# N32F030 register map
File version: 1.0
Registers are 32-bit, read-write, reset 0x0 unless marked. A register's access mark holds for its fields unless they carry their own. Offsets are from the block's base; [hi:lo] are bit positions; {n}, {i} and the like mark numbered series; 'fields as' and 'values as' point back to an identical list.

## EPWM — EPWM Register Map
Base 0x40040000
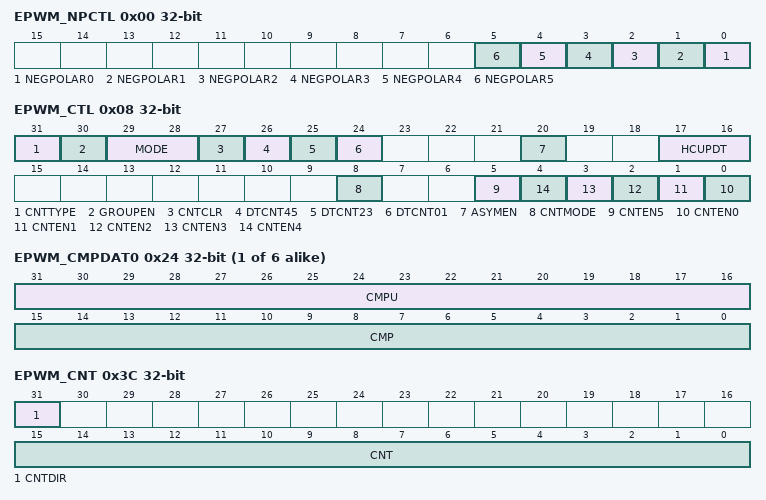
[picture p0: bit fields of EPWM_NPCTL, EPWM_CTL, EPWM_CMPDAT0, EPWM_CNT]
0x00 EPWM_NPCTL — EPWM Negative Polarity Control Register
  [all] fields
    0=PWM output is active high; 1=PWM output is active low
  [n] NEGPOLAR{n} (n=0..5) — PWM{n} Negative Polarity Control. The register bit controls polarity/active state of real PWM output.
0x04 EPWM_CLKDIV — EPWM Clock Select Register
  [3:0] CLKDIV — EPWM Clock Divider (9 Step Divider). Select clock input for PWM timer
    0=1 (HCLK / 2^0); 1=1/2 (HCLK / 2^1); 2=1/4 (HCLK / 2^2); 3=1/8 (HCLK / 2^3); 4=1/16 (HCLK / 2^4); 5=1/32 (HCLK / 2^5); 6=1/64 (HCLK / 2^6); 7=1/128 (HCLK / 2^7); 8=1/256 (HCLK / 2^8)
0x08 EPWM_CTL — EPWM Control Register
  [31] CNTTYPE — PWM Aligned Type Selection
    0=Edge-aligned type; 1=Center-aligned type
  [30] GROUPEN — Group Bit
    0=The signals timing of PWM0, PWM2 and PWM4 are independent; 1=Unify the signals timing of PWM0, PWM2 and PWM4 in the same phase which is controlled by PWM0
  [29:28] MODE — PWM Operating Mode Selection. Note: If th complementary mode is selected, the deadtime insertion is active automatically.
    0=Independent mode; 1=Complementary mode
  [27] CNTCLR — Clear PWM Counter Control Bit. Note: It is automatically cleared by hardware.
    0=Do not clear PWM counter; 1=16-bit PWM counter cleared to 0x000
  [26] DTCNT45 — Dead-zone 4 Generator Enable/Disable (PWM4 and PWM5 Pair for PWM Group). Note: When the dead-zone generator is enabled, the pair of PWM4 and PWM5 becomes a complementary pair for PWM group.
    0=Dead-zone 4 Generator Disabled; 1=Dead-zone 4 Generator Enabled
  [25] DTCNT23 — Dead-zone 2 Generator Enable/Disable (PWM2 and PWM3 Pair for PWM Group). Note: When the dead-zone generator is enabled, the pair of PWM2 and PWM3 becomes a complementary pair for PWM group.
    0=Dead-zone 2 Generator Disabled; 1=Dead-zone 2 Generator Enabled
  [24] DTCNT01 — Dead-zone 0 Generator Enable/Disable (PWM0 and PWM1 Pair for PWM Group). Note: When the dead-zone generator is enabled, the pair of PWM0 and PWM1 becomes a complementary pair for PWM group.
    0=Dead-zone 0 Generator Disabled; 1=Dead-zone 0 Generator Enabled
  [20] ASYMEN — Asymmetric Mode in Center-aligned Type
    0=Symmetric mode in center-aligned type; 1=Asymmetric mode in center-aligned type
  [17:16] HCUPDT — Half Cycle Update Enable for Center-aligned Type
    0=Update PERIOD CMP at pwm_counter = PERIOD (Period); 1=Update PERIOD CMP at pwm_counter = 0; 2=Update PERIOD CMP at half cycle (counter = 0 PERIOD, both update); 3=Update PERIOD CMP at pwm_counter = PERIOD (Period)
  [8] CNTMODE — PWM-timer Auto-reload/One-shot Mode
    0=One-shot mode; 1=Auto-reload mode
  [5] CNTEN5 — PWM-generator 5 Enable/Disable Start Run
    0=Corresponding PWM-timer running Stopped; 1=Corresponding PWM-timer start run Enabled
  [n] CNTEN{n} (n=0..4) — PWM- Generator {n} Enable/Disable Start Run
    values as CNTEN5
0x0C EPWM_PERIOD — EPWM Period Counter Register
  [15:0] PERIOD — PWM Counter/Timer Loaded Value. PERIODn determines the PWM Period. Edge-aligned mode: where xy, could be 01, 23, 45 depending on the selected PWM channel. Note: Any write to PERIODn will take effect in next PWM cycle.
{0x24+4i} EPWM_CMPDAT{i} (i=0..5) — EPWM Comparator Register {i}
  [31:16] CMPU — PWM Comparator Register for UP Counter in Center-aligned Asymmetric Mode. CMPU PERIOD: @ up counter PWM output is keep to Max. duty.
  [15:0] CMP — PWM Comparator Register. CMP determines the PWM Duty. Edge-aligned mode: where xy, could be 01, 23, 45 depending on the selected PWM channel. Note: Any write to CMPn will take effect in next PWM cycle.
0x3C EPWM_CNT ro — EPWM Data Register
  [31] CNTDIR — PWM Counter (Up/Down) Direction
    0=PWM counter is down counting; 1=PWM counter is up counting
  [15:0] CNT — PWM Data Register. User can monitor CNT to know the current value in 16-bit down counter.
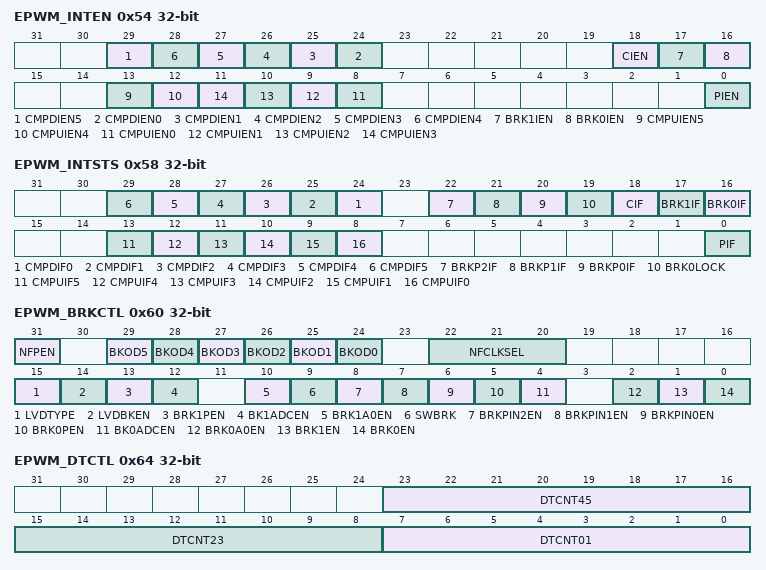
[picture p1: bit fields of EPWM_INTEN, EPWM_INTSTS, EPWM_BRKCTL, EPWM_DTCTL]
0x54 EPWM_INTEN — EPWM Interrupt Enable Register
  [29] CMPDIEN5 — PWM Channel 5 DOWN Interrupt Enable Control. DOWN for Edge-aligned and Center-aligned
    0=Interruptcompare Disabled; 1=Interruptwhen EPWM_CH5 PWM DOWN counter reaches EPWM_CMPDAT5 Enabled
  [n+24] CMPDIEN{n} (n=0..4) — PWM Channel {n} DOWN Interrupt Enable Control. DOWN for Edge-aligned and Center-aligned
    0=Interruptcompare Disabled; 1=interruptwhen EPWM_CH{n} PWM DOWN counter reaches EPWM_CMPDAT{n} Enabled
  [18] CIEN — PWM Central Interrupt Enable Control for Center-aligned only
    0=Interruptwhen EPWM Central Enabled; 1=Interruptwhen EPWM Central Enabled
  [17] BRK1IEN — Fault Brake1 Interrupt Enable Control
    0=BRK1IF trigger PWM interrupt Disabed; 1=BRK1IF trigger PWM interrupt Enabled
  [16] BRK0IEN — Fault Brake0 Interrupt Enable Control
    0=BRK0IF trigger PWM interrupt Disabled; 1=BRK0IF trigger PWM interrupt Enabled
  [13] CMPUIEN5 — PWM Channel 5 UP Interrupt Enable Control. UP for Center-aligned only
    0=PWM Channel 5 UP Interrupt Disabled; 1=Interruptwhen EPWM_CH5 PWM UP counter reaches EPWM_CMPDAT5 Enabled
  [12] CMPUIEN4 — PWM Channel 4 UP Interrupt Enable Control. UP for Center-aligned only
    0=EPWM_CH4 PWM UP counter reaches EPWM_CMPDAT4 interrupt Disabled; 1=EPWM_CH4 PWM UP counter reaches EPWM_CMPDAT4 interrupt Enabled
  [n+8] CMPUIEN{n} (n=0..3) — PWM Channel {n} UP Interrupt Enable Control. UP for Center-aligned only
    0=EPWM_CH{n} PWM UP counter reaches EPWM_CMPDAT{n} interruptDisabled; 1=EPWM_CH{n} PWM UP counter reaches EPWM_CMPDAT{n} interruptEnabled
  [0] PIEN — PWM Channel 0 Period Interrupt Enable Control for Edge-aligned and Center-aligned
    0=EPWM Period interruptDisabled; 1=EPWM Period interruptEnabled
0x58 EPWM_INTSTS — EPWM Interrupt Status Register
  [n+24] CMPDIF{n} (n=0..5) — PWM Channel {n} DOWN Interrupt Flag. Flag is set by hardware when a channel {n} PWM DOWN counter reaches EPWM_CMPDAT{n}. Software can write 1 to clear this bit.
  [22] BRKP2IF — BRK Pin2 Status Flag. Flag is set by pin PWM_BRK_P2 with low pulse event. Software can write 1 to clear this bit.
  [21] BRKP1IF — BRK Pin1 Status Flag. Flag is set by pin PWM_BRK_P1 with low pulse event. Software can write 1 to clear this bit.
  [20] BRKP0IF — BRK Pin0 Status Flag. Flag is set by pin PWM_BRK_P0 with low pulse event. Software can write 1 to clear this bit.
  [19] BRK0LOCK — PWM Brake0 Locked. Note: Software can write 1 to clear this bit.
    0=PWM Brake does not recognize a falling signal at BKP0; 1=When PWM Brake detects a falling signal at pin BKP0, this flag will be set to high, when this bit set high, it helps breaking PWM output even interrupt flag BRK0IF was cleared by CPU before jumping out from sub-routine
  [18] CIF — PWM Channel 0 Central Interrupt Flag. Flag is set by hardware when PWM down counter reaches zero point. Software can write 1 to clear this bit.
  [17] BRK1IF — PWM Brake1 Flag. Note: Software can write 1 to clear this bit.
    0=PWM Brake does not recognize a falling signal at BKP1; 1=When PWM Brake detects a falling signal at pin BKP1, this flag will be set to high
  [16] BRK0IF — PWM Brake0 Flag. Note: Software can write 1 to clear this bit.
    0=PWM Brake does not recognize a falling signal at BKP0; 1=When PWM Brake detects a falling signal at pin BKP0, this flag will be set to high
  [13] CMPUIF5 — PWM Channel 5 UP Interrupt Flag. Flag is set by hardware when a channel 5 PWM UP counter reaches PWM_CMPDAT5. Software can write 1 to clear this bit.
  [12] CMPUIF4 — PWM Channel 4 UP Interrupt Flag. Flag is set by hardware when a channel 4 PWM UP counter reaches PWM_CMPDAT4. Software can write 1 to clear this bit.
  [11] CMPUIF3 — PWM Channel 3 UP Interrupt Flag. Flag is set by hardware when a channel 3 PWMUP counter reaches PWM_CMPDAT3. Software can write 1 to clear this bit.
  [10] CMPUIF2 — PWM Channel 2 UP Interrupt Flag. Flag is set by hardware when a channel 2 PWM UP counter reaches PWM_CMPDAT2. Software can write 1 to clear this bit.
  [9] CMPUIF1 — PWM Channel 1 UP Interrupt Flag. Flag is set by hardware when a channel 1 PWM UP counter reaches PWM_CMPDAT1. Software can write 1 to clear this bit.
  [8] CMPUIF0 — PWM Channel 0 UP Interrupt Flag. Flag is set by hardware when a channel 0 PWM UP counter reaches PWM_CMPDAT0. Software can write 1 to clear this bit.
  [0] PIF — PWM Channel 0 Period Interrupt Flag. Edge-aligned mode: Flag is set by hardware when PWM down counter reaches zero point. Center-aligned mode: Flag is set by hardware when PWM down counter reaches zero point and then up counter reaches EPWM_PERIOD. Software can write 1 to clear this bit.
0x5C EPWM_RESDLY — EPWM BRK Low Voltage Detect Resume Delay
  [11:0] DELAY — PWM BRK Low Voltage Detect Resume Delay. 12 bits Down-Counter
0x60 EPWM_BRKCTL — EPWM Fault Brake Control Register
  [31] NFPEN — Noise Filter for External Brake Input Pin (BRAKE) Enable Control
    0=Noise Filter for External Brake Input Pin (BRAKE) Disabled; 1=Noise Filter for External Brake Input Pin (BRAKE) Enabled
  [n+24] BKOD{n} (n=0..5) — PWM Channel {n} Brake Output Selection
    0=PWM output low when fault brake conditions asserted; 1=PWM output high when fault brake conditions asserted
  [22:20] NFCLKSEL — Noise Filter Clock Pre-divide Selection. To determine the sampling frequency of the Noise Filter clock.
    0=EPWM_CLK; 1=EPWM _CLK/2; 2=EPWM _CLK/4; 3=EPWM _CLK/8; 4=EPWM _CLK/16; 5=EPWM _CLK/32; 6=EPWM _CLK/64; 7=EPWM _CLK/128
  [15] LVDTYPE — Low-level Detection Resume Type
    0=Brake resume at BRK resume delay counter counting to 0; 1=Brake resume at period edge
  [14] LVDBKEN — Low-level Detection Trigger PWM Brake Function 1 Enable Control
    0=Brake Function 1 triggered by Low-level detection Disabled; 1=Brake Function 1 triggered by Low-level detection Enabled
  [13] BRK1PEN — BRK1 Source From External Pin Enable Control
    0=BRK1 Source From External Pin Disabled; 1=BRK1 Source From External Pin Enabled
  [12] BK1ADCEN — BRK1 Source From ADC Enable Control
    0=BRK1 Source From ADC Disabled; 1=BRK1 Source From ADC Enabled
  [10] BRK1A0EN — BRK1 Source From ACMP0 Enable Control
    0=BRK1 Source From ACMP0 Disabled; 1=BRK1 Source From ACMP0 Enabled
  [9] SWBRK — Software Break
    0=Software break and back to normal PWM function Disabled; 1=Issue Software break Enabled
  [8] BRKPIN2EN — BRK Source From External Pin 2 Enable Control
    0=BRK Source From External PWM_BRK_P2 Disabled; 1=BRK Source From External PWM_BRK_P2 Enabled
  [7] BRKPIN1EN — BRK Source From External Pin 1 Enable Control
    0=BRK Source From External PWM_BRK_P1 Disabled; 1=BRK Source From External PWM_BRK_P1 Enabled
  [6] BRKPIN0EN — BRK Source From External Pin 0 Enable Control
    0=BRK Source From External PWM_BRK_P0 Disabled; 1=BRK Source From External PWM_BRK_P0 Enabled
  [5] BRK0PEN — BRK0 Source From External Pin Enable Control
    0=BRK0 Source From External Pin Disabled; 1=BRK0 Source From External Pin Enabled
  [4] BK0ADCEN — BRK0 Source From ADC Enable Control
    0=BRK0 Source From ADC Disabled; 1=BRK0 Source From ADC Enabled
  [2] BRK0A0EN — BRK0 Source From ACMP0 Enable Control
    0=BRK0 Source From ACMP0 Disabled; 1=BRK0 Source From ACMP0 Enabled
  [1] BRK1EN — Brake1 Function Enable Control
    0=Brake1 detect function Disabled; 1=Brake1 detect function Enabled
  [0] BRK0EN — Brake0 Function Enable Control
    0=Brake0 detect function Disabled; 1=Brake0 detect function Enabled
0x64 EPWM_DTCTL — EPWM Dead-zone Interval Register
  [23:16] DTCNT45 — Dead-zone Interval Register for Pair of Channel4 and Channel5 (PWM4 and PWM5 Pair). These 8 bits determine dead-zone length. The unit time of dead-zone length is received from corresponding EPWM_CLKDIV bits.
  [15:8] DTCNT23 — Dead-zone Interval Register for Pair of Channel2 and Channel3 (PWM2 and PWM3 Pair). These 8 bits determine dead-zone length. The unit time of dead-zone length is received from corresponding EPWM_CLKDIV bits.
  [7:0] DTCNT01 — Dead-zone Interval Register for Pair of Channel0 and Channel1 (PWM0 and PWM1 Pair). These 8 bits determine dead-zone length. The unit time of dead-zone length is received from corresponding EPWM_CLKDIV bits.
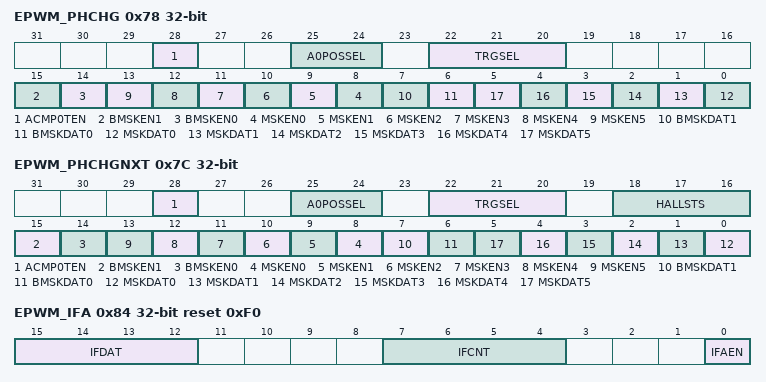
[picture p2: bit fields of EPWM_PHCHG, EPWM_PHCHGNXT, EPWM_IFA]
0x78 EPWM_PHCHG — EPWM Phase Changed Register
  [28] ACMP0TEN — ACMP0 Trigger Function Enable Control
    0=ACMP0 trigger PWM function Disabled; 1=ACMP0 trigger PWM function Enabled
  [25:24] A0POSSEL — Alternative Comparator 0 Positive Input Selection. Select the positive input source of ACMP0.
    0=Select ACMP0_P0 (PB.0) as the input of ACMP0; 1=Select ACMP0_P1 (PB.1) as the input of ACMP0; 2=Select ACMP0_P2 (PB.2) as the input of ACMP0; 3=Select ACMP0_P3 (PC.1) as the input of ACMP0
  [22:20] TRGSEL — Phase Change Trigger Selection. Select the trigger condition to load PHCHG from PHCHG_NXT. When the trigger condition occurs it will load EPWM_PHCHG with PHCHG_NXT. Phase Change: PWM outputs are masked according with the definition of MSKENn and MSKDATn in EPWM_PHCHG.
    0=Triggered by TMR0_MATCH event; 1=Triggered by TMR1_MATCH event; 2=Triggered by CAPPHG_TRG from ECAP. (CAPTF0 | CAPTF1 | CAPTF2); 3=Triggered by HALLSTS (EPWM_PHCHGNXT[18:16]) matched (CAP2, CAP1, CAP0) in ECAP; 4=Triggered by ACMP0_PBRK event; 6=Triggered by TMR2_MATCH event; 7=Auto Phase Change Function Disabled
  [15] BMSKEN1 — Enable BPWM1 Mask Function. Note: This bit effects BPWM1 only when BPWM_CTL.BP1SYNEPWM is set
    0=BPWM1 Mask Function Disabled; 1=BPWM1 Mask Function Enabled
  [14] BMSKEN0 — Enable BPWM0 Mask Function. Note: This bit effects BPWM0 only when BPWM_CTL.BP0SYNEPWM is set
    0=BPWM0 Mask Function Disabled; 1=BPWM0 Mask Function Enabled
  [n+8] MSKEN{n} (n=0..5) — Enable PWM{n} Mask Function
    0=PWM{n} Mask Function Disabled; 1=PWM{n} Mask Function Enabled
  [7] BMSKDAT1 — Enable BPWM1 Mask Data. Note: This bit effects BPWM1 only when BPWM_CTL.BP1SYNEPWM is set
    0=BPWM1 state is masked with zero; 1=BPWM1 state is masked with one
  [6] BMSKDAT0 — Enable BPWM0 Mask Data. Note: This bit effects BPWM0 only when BPWM_CTL.BP0SYNEPWM is set
    0=BPWM0 state is masked with zero; 1=BPWM0 state is masked with one
  [n] MSKDAT{n} (n=0..5) — Enable PWM{n} Mask Data
    0=PWM{n} state is masked with zero; 1=PWM{n} state is masked with one
0x7C EPWM_PHCHGNXT — EPWM Next Phase Change Register
  [28] ACMP0TEN — ACMP0 Trigger Function Control Preset Bit. This bit will be load to bit ACMP0TEN in EPWM_PHCHG when load trigger condition occurs. Refer to register EPWM_PHCHG for detailed definition.
  [25:24] A0POSSEL — Alternative Comparator 0 Positive Input Selection Preset Bits. This bit field will be load to bit field A0POSSEL in EPWM_PHCHG when load trigger condition occurs. Refer to register EPWM_PHCHG for detailed definition.
  [22:20] TRGSEL — Phase Change Trigger Selection Preset Bits. This bit field will be load to bit field TRGSEL in EPWM_PHCHG when load trigger condition occurs. Refer to register EPWM_PHCHG for detailed definition.
    values as EPWM_PHCHG.TRGSEL
  [18:16] HALLSTS — Predicted Next HALL State. This bit field indicates the predicted hall state at next commutation. the hardware will compare bits (CAP2, CAP1, CAP0) in timer 2 with HALLSTS [2:0] when any hall state change occurs. If the comparison is matched it will trigger phase change function.
  [15] BMSKEN1 — Enable BPWM1 Mask Function Preset Bit. This bit will be load to bit MSKEN5 in EPWM_PHCHG when load trigger condition occurs. Refer to register EPWM_PHCHG for detailed definition. Note: This bit effects BPWM1 only when BPWM_CTL.BP1SYNEPWM is set
  [14] BMSKEN0 — Enable BPWM0 Mask Function Preset Bit. This bit will be load to bit MSKEN4 in EPWM_PHCHG when load trigger condition occurs. Refer to register EPWM_PHCHG for detailed definition. Note: This bit effects BPWM0 only when BPWM_CTL.BP0SYNEPWM is set
  [n+8] MSKEN{n} (n=0..5) — Enable PWM{n} Mask Function Preset Bit. This bit will be load to bit MSKEN{n} in EPWM_PHCHG when load trigger condition occurs. Refer to register EPWM_PHCHG for detailed definition.
  [7] BMSKDAT1 — Enable BPWM1 Mask Data Preset Bit. This bit will be load to bit BMSKDAT1 in EPWM_PHCHG when load trigger condition occurs. Refer to register EPWM_PHCHG for detailed definition. Note: This bit effects BPWM1 only when BPWM_CTL.BP1SYNEPWM is set
  [6] BMSKDAT0 — Enable BPWM0 Mask Data Preset Bit. This bit will be load to bit BMSKDAT0 in EPWM_PHCHG when load trigger condition occurs. Refer to register EPWM_PHCHG for detailed definition. Note: This bit effects BPWM0 only when BPWM_CTL.BP0SYNEPWM is set
  [n] MSKDAT{n} (n=0..5) — Enable PWM{n} Mask Data Preset Bit. This bit will be load to bit MSKDAT{n} in EPWM_PHCHG when load trigger condition occurs. Refer to register EPWM_PHCHG for detailed definition.
0x80 EPWM_PHCHGALT — EPWM Phase Change Alternative Control Register
  [0] POSCTL0 — Positive Input Control for ACMP0. Note: Register ACMP_CTL0 is describe in Comparator Controller chapter
    0=The input of ACMP0 is controlled by ACMP_CTL0; 1=The input of ACMP0 is controlled by A0POSSEL in EPWM_PHCHG register
0x84 EPWM_IFA reset 0xF0 — EPWM Period Interrupt Accumulation Control Register
  [15:12] IFDAT ro — Period Interrupt Down-counter Data Register (Read Only). When IFAEN is set, IFDAT will decrease when every PWM Interrupt flag is set, and when IFDAT reaches 0, the PWM interrupt will occurred and IFCNT will reload to IFDAT.
  [7:4] IFCNT wo — Period Interrupt Accumulation Counter Value Setting Register (Write Only). 16 step Down-Counter value setting register. When IFAEN is set, IFCNT value will load into IFDAT and decrase gradually.
  [0] IFAEN — Enable Period Interrupt Accumulation Function
    0=Period Interrupt Accumulation Disabled; 1=Period Interrupt Accumulation Enabled
